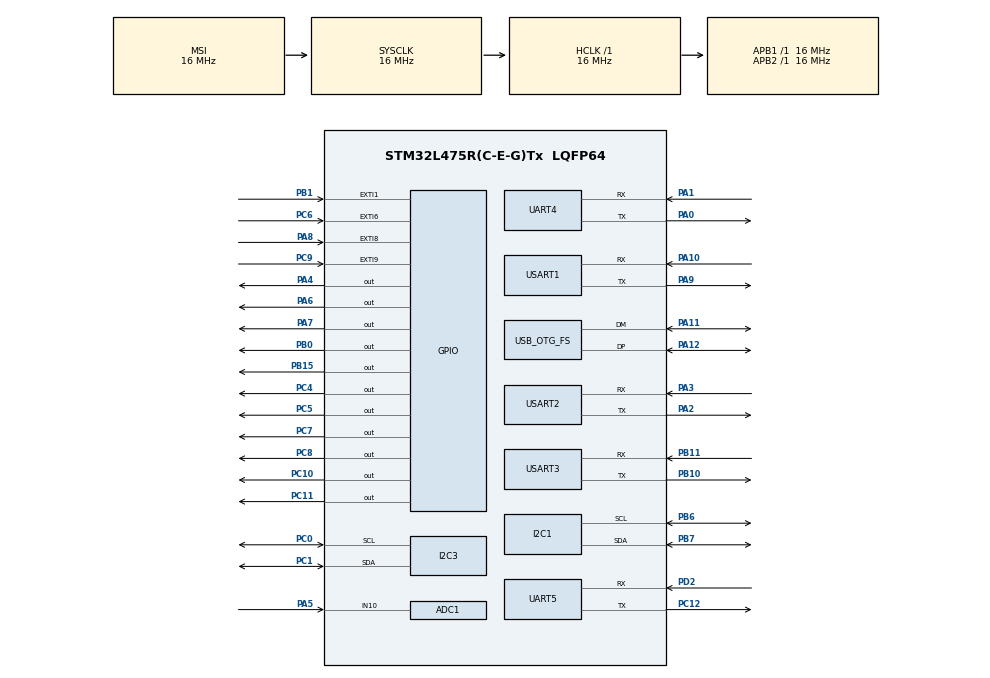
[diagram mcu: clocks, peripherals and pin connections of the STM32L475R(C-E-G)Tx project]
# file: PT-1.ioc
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ADC1.Channel-1\#ChannelRegularConversion=ADC_CHANNEL_10
ADC1.NbrOfConversionFlag=1
ADC1.OffsetNumber-1\#ChannelRegularConversion=ADC_OFFSET_NONE
ADC1.Rank-1\#ChannelRegularConversion=1
ADC1.SamplingTime-1\#ChannelRegularConversion=ADC_SAMPLETIME_2CYCLES_5
ADC1.master=1
I2C1.Timing=0x00303D5B
I2C3.Timing=0x00303D5B
Mcu.Family=STM32L4
Mcu.Name=STM32L475R(C-E-G)Tx
Mcu.Package=LQFP64
NVIC.OTG_FS_IRQn=true\:0\:0\:false\:false\:true\:false\:true
NVIC.PriorityGroup=NVIC_PRIORITYGROUP_4
PA0.Mode=Asynchronous
PA0.Signal=UART4_TX
PA1.Mode=Asynchronous
PA1.Signal=UART4_RX
PA10.Mode=Asynchronous
PA10.Signal=USART1_RX
PA11.Mode=Device_Only
PA11.Signal=USB_OTG_FS_DM
PA12.Mode=Device_Only
PA12.Signal=USB_OTG_FS_DP
PA2.Mode=Asynchronous
PA2.Signal=USART2_TX
PA3.Mode=Asynchronous
PA3.Signal=USART2_RX
PA4.Signal=GPIO_Output
PA5.Signal=ADCx_IN10
PA6.Signal=GPIO_Output
PA7.Signal=GPIO_Output
PA8.Signal=GPXTI8
PA9.Mode=Asynchronous
PA9.Signal=USART1_TX
PB0.Signal=GPIO_Output
PB1.Signal=GPXTI1
PB10.Mode=Asynchronous
PB10.Signal=USART3_TX
PB11.Mode=Asynchronous
PB11.Signal=USART3_RX
PB15.Signal=GPIO_Output
PB6.Mode=I2C
PB6.Signal=I2C1_SCL
PB7.Mode=I2C
PB7.Signal=I2C1_SDA
PC0.Mode=I2C
PC0.Signal=I2C3_SCL
PC1.Mode=I2C
PC1.Signal=I2C3_SDA
PC10.Signal=GPIO_Output
PC11.Signal=GPIO_Output
PC12.Mode=Asynchronous
PC12.Signal=UART5_TX
PC4.Signal=GPIO_Output
PC5.Signal=GPIO_Output
PC6.Signal=GPXTI6
PC7.Signal=GPIO_Output
PC8.Signal=GPIO_Output
PC9.Signal=GPXTI9
PD2.Mode=Asynchronous
PD2.Signal=UART5_RX
PH0-OSC_IN\ (PH0).Mode=HSE-External-Oscillator
PH0-OSC_IN\ (PH0).Signal=RCC_OSC_IN
PH1-OSC_OUT\ (PH1).Mode=HSE-External-Oscillator
PH1-OSC_OUT\ (PH1).Signal=RCC_OSC_OUT
ProjectManager.HeapSize=0x200
ProjectManager.StackSize=0x400
ProjectManager.TargetToolchain=MDK-ARM V5
RCC.ADCFreq_Value=48000000
RCC.AHBFreq_Value=16000000
RCC.APB1Freq_Value=16000000
RCC.APB1TimFreq_Value=16000000
RCC.APB2Freq_Value=16000000
RCC.APB2TimFreq_Value=16000000
RCC.CK48CLockSelection=RCC_USBCLKSOURCE_PLL
RCC.CortexFreq_Value=16000000
RCC.HCLKFreq_Value=16000000
RCC.HSE_VALUE=24000000
RCC.HSI_VALUE=16000000
RCC.LSE_VALUE=32768
RCC.MSIClockRange=RCC_MSIRANGE_8
RCC.MSI_VALUE=16000000
RCC.PLLM=2
RCC.PLLN=16
RCC.PLLQ=RCC_PLLQ_DIV4
RCC.PLLR=RCC_PLLR_DIV6
RCC.PLLSourceVirtual=RCC_PLLSOURCE_HSE
RCC.SYSCLKFreq_VALUE=16000000
RCC.USBFreq_Value=48000000
RCC.VCOOutputFreq_Value=192000000
SH.ADCx_IN10.0=ADC1_IN10,IN10-Single-Ended
USART1.VirtualMode-Asynchronous=VM_ASYNC
USART2.OverrunDisableParam=ADVFEATURE_OVERRUN_ENABLE
USART2.VirtualMode-Asynchronous=VM_ASYNC
USART3.VirtualMode-Asynchronous=VM_ASYNC
USB_DEVICE.CLASS_NAME_FS=CDC
USB_DEVICE.VirtualMode=Cdc
USB_DEVICE.VirtualModeFS=Cdc_FS
USB_OTG_FS.VirtualMode=Device_Only
VP_USB_DEVICE_VS_USB_DEVICE_CDC_FS.Mode=CDC_FS
board=custom

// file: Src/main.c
/* USER CODE BEGIN Header */
/**
  ******************************************************************************
  * @file           : main.c
  * @brief          : Main program body
  ******************************************************************************
  * @attention
  *
  * <h2><center>&copy; Copyright (c) 2023 STMicroelectronics.
  * All rights reserved.</center></h2>
  *
  * This software component is licensed by ST under BSD 3-Clause license,
  * the "License"; You may not use this file except in compliance with the
  * License. You may obtain a copy of the License at:
  *                        opensource.org/licenses/BSD-3-Clause
  *
  ******************************************************************************
  */
/* USER CODE END Header */

#include "main.h"
#include "adc.h"
#include "i2c.h"
#include "usart.h"
#include "usb_device.h"
#include "gpio.h"

void SystemClock_Config(void);
/* USER CODE BEGIN PFP */
void USB_Status_Init(void);
/* USER CODE END PFP */

int main(void)
{

  /* MCU Configuration--------------------------------------------------------*/

  /* Reset of all peripherals, Initializes the Flash interface and the Systick. */
  HAL_Init();

  /* Configure the system clock */
  SystemClock_Config();

  /* USER CODE BEGIN SysInit */
  USB_Status_Init();
  /* USER CODE END SysInit */

  /* Initialize all configured peripherals */
  MX_GPIO_Init();
  MX_ADC1_Init();
  MX_I2C1_Init();
  MX_I2C3_Init();
  MX_UART4_Init();
  MX_UART5_Init();
  MX_USART1_UART_Init();
  MX_USART2_UART_Init();
  MX_USART3_UART_Init();
  MX_USB_DEVICE_Init();

  /* Infinite loop */
  while (1)
  {

  }
}

void SystemClock_Config(void)
{
  RCC_OscInitTypeDef RCC_OscInitStruct = {0};
  RCC_ClkInitTypeDef RCC_ClkInitStruct = {0};
  RCC_PeriphCLKInitTypeDef PeriphClkInit = {0};

  /** Initializes the CPU, AHB and APB busses clocks
  */
  RCC_OscInitStruct.OscillatorType = RCC_OSCILLATORTYPE_HSE|RCC_OSCILLATORTYPE_MSI;
  RCC_OscInitStruct.HSEState = RCC_HSE_ON;
  RCC_OscInitStruct.MSIState = RCC_MSI_ON;
  RCC_OscInitStruct.MSICalibrationValue = 0;
  RCC_OscInitStruct.MSIClockRange = RCC_MSIRANGE_8;
  RCC_OscInitStruct.PLL.PLLState = RCC_PLL_ON;
  RCC_OscInitStruct.PLL.PLLSource = RCC_PLLSOURCE_HSE;
  RCC_OscInitStruct.PLL.PLLM = 2;
  RCC_OscInitStruct.PLL.PLLN = 16;
  RCC_OscInitStruct.PLL.PLLP = RCC_PLLP_DIV7;
  RCC_OscInitStruct.PLL.PLLQ = RCC_PLLQ_DIV4;
  RCC_OscInitStruct.PLL.PLLR = RCC_PLLR_DIV6;
  if (HAL_RCC_OscConfig(&RCC_OscInitStruct) != HAL_OK)
  {
    Error_Handler();
  }
  /** Initializes the CPU, AHB and APB busses clocks
  */
  RCC_ClkInitStruct.ClockType = RCC_CLOCKTYPE_HCLK|RCC_CLOCKTYPE_SYSCLK
                              |RCC_CLOCKTYPE_PCLK1|RCC_CLOCKTYPE_PCLK2;
  RCC_ClkInitStruct.SYSCLKSource = RCC_SYSCLKSOURCE_MSI;
  RCC_ClkInitStruct.AHBCLKDivider = RCC_SYSCLK_DIV1;
  RCC_ClkInitStruct.APB1CLKDivider = RCC_HCLK_DIV1;
  RCC_ClkInitStruct.APB2CLKDivider = RCC_HCLK_DIV1;

  if (HAL_RCC_ClockConfig(&RCC_ClkInitStruct, FLASH_LATENCY_0) != HAL_OK)
  {
    Error_Handler();
  }
  PeriphClkInit.PeriphClockSelection = RCC_PERIPHCLK_USART1|RCC_PERIPHCLK_USART2
                              |RCC_PERIPHCLK_USART3|RCC_PERIPHCLK_UART4
                              |RCC_PERIPHCLK_UART5|RCC_PERIPHCLK_I2C1
                              |RCC_PERIPHCLK_I2C3|RCC_PERIPHCLK_USB
                              |RCC_PERIPHCLK_ADC;
  PeriphClkInit.Usart1ClockSelection = RCC_USART1CLKSOURCE_PCLK2;
  PeriphClkInit.Usart2ClockSelection = RCC_USART2CLKSOURCE_PCLK1;
  PeriphClkInit.Usart3ClockSelection = RCC_USART3CLKSOURCE_PCLK1;
  PeriphClkInit.Uart4ClockSelection = RCC_UART4CLKSOURCE_PCLK1;
  PeriphClkInit.Uart5ClockSelection = RCC_UART5CLKSOURCE_PCLK1;
  PeriphClkInit.I2c1ClockSelection = RCC_I2C1CLKSOURCE_PCLK1;
  PeriphClkInit.I2c3ClockSelection = RCC_I2C3CLKSOURCE_PCLK1;
  PeriphClkInit.AdcClockSelection = RCC_ADCCLKSOURCE_PLLSAI1;
  PeriphClkInit.UsbClockSelection = RCC_USBCLKSOURCE_PLL;
  PeriphClkInit.PLLSAI1.PLLSAI1Source = RCC_PLLSOURCE_HSE;
  PeriphClkInit.PLLSAI1.PLLSAI1M = 2;
  PeriphClkInit.PLLSAI1.PLLSAI1N = 8;
  PeriphClkInit.PLLSAI1.PLLSAI1P = RCC_PLLP_DIV7;
  PeriphClkInit.PLLSAI1.PLLSAI1Q = RCC_PLLQ_DIV2;
  PeriphClkInit.PLLSAI1.PLLSAI1R = RCC_PLLR_DIV2;
  PeriphClkInit.PLLSAI1.PLLSAI1ClockOut = RCC_PLLSAI1_ADC1CLK;
  if (HAL_RCCEx_PeriphCLKConfig(&PeriphClkInit) != HAL_OK)
  {
    Error_Handler();
  }
  /** Configure the main internal regulator output voltage
  */
  if (HAL_PWREx_ControlVoltageScaling(PWR_REGULATOR_VOLTAGE_SCALE1) != HAL_OK)
  {
    Error_Handler();
  }
}

/* USER CODE BEGIN 4 */
void USB_Status_Init(void)
{
    GPIO_InitTypeDef GPIO_InitStruct = {0};

    /* GPIO Ports Clock Enable */
    __HAL_RCC_GPIOA_CLK_ENABLE();

    /*Configure GPIO pin Output Level */
    HAL_GPIO_WritePin(GPIOA, GPIO_PIN_11 | GPIO_PIN_12, GPIO_PIN_RESET);

    /*Configure GPIO pin : W25Q256_CS_Pin */
    GPIO_InitStruct.Pin = GPIO_PIN_11 | GPIO_PIN_12;
    GPIO_InitStruct.Mode = GPIO_MODE_OUTPUT_PP;
    GPIO_InitStruct.Pull = GPIO_PULLDOWN;
    GPIO_InitStruct.Speed = GPIO_SPEED_FREQ_LOW;
    HAL_GPIO_Init(GPIOA, &GPIO_InitStruct);

    //假如不行的话，下面的延时加长即可。
    HAL_Delay(10);
}
/* USER CODE END 4 */

void Error_Handler(void)
{
}

/************************ (C) COPYRIGHT STMicroelectronics *****END OF FILE****/
